# CH32X035 register map
Vendor: WCH Ltd.; File version: 1.3
Registers are 32-bit, read-write, reset 0x0 unless marked. A register's access mark holds for its fields unless they carry their own. Offsets are from the block's base; [hi:lo] are bit positions; {n}, {i} and the like mark numbered series.

## USART1 — Universal synchronous asynchronous receiver transmitter
Base 0x40013800
Same registers: USART2 0x40004400, USART3 0x40004800, UART4 0x40004C00
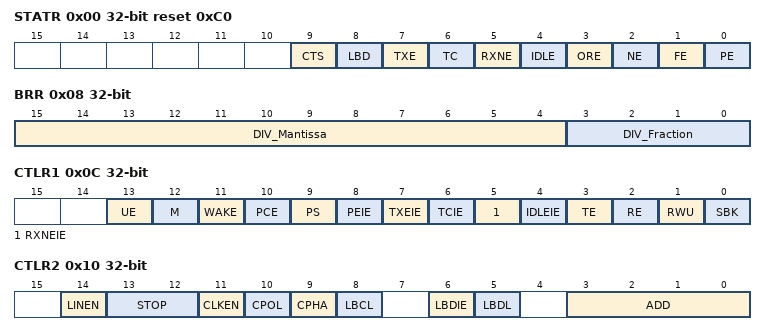
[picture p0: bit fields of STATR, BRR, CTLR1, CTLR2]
0x00 STATR access per field reset 0xC0 — Status register
  [9] CTS rw — CTS flag
  [8] LBD rw — LIN break detection flag
  [7] TXE ro — Transmit data register empty
  [6] TC rw — Transmission complete
  [5] RXNE rw — Read data register not empty
  [4] IDLE ro — IDLE line detected
  [3] ORE ro — Overrun error
  [2] NE ro — Noise error flag
  [1] FE ro — Framing error
  [0] PE ro — Parity error
0x04 DATAR — Data register
  [8:0] DR — Data value
0x08 BRR — Baud rate register
  [15:4] DIV_Mantissa — mantissa of USARTDIV
  [3:0] DIV_Fraction — fraction of USARTDIV
0x0C CTLR1 — Control register 1
  [13] UE — USART enable
  [12] M — Word length
  [11] WAKE — Wakeup method
  [10] PCE — Parity control enable
  [9] PS — Parity selection
  [8] PEIE — PE interrupt enable
  [7] TXEIE — TXE interrupt enable
  [6] TCIE — Transmission complete interrupt enable
  [5] RXNEIE — RXNE interrupt enable
  [4] IDLEIE — IDLE interrupt enable
  [3] TE — Transmitter enable
  [2] RE — Receiver enable
  [1] RWU — Receiver wakeup
  [0] SBK — Send break
0x10 CTLR2 — Control register 2
  [14] LINEN — LIN mode enable
  [13:12] STOP — STOP bits
  [11] CLKEN — Clock enable
  [10] CPOL — Clock polarity
  [9] CPHA — Clock phase
  [8] LBCL — Last bit clock pulse
  [6] LBDIE — LIN break detection interrupt enable
  [5] LBDL — lin break detection length
  [3:0] ADD — Address of the USART node
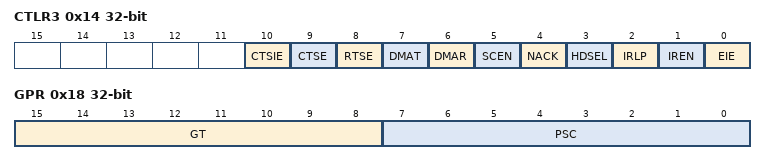
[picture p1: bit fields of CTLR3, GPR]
0x14 CTLR3 — Control register 3
  [10] CTSIE — CTS interrupt enable
  [9] CTSE — CTS enable
  [8] RTSE — RTS enable
  [7] DMAT — DMA enable transmitter
  [6] DMAR — DMA enable receiver
  [5] SCEN — Smartcard mode enable
  [4] NACK — Smartcard NACK enable
  [3] HDSEL — Half-duplex selection
  [2] IRLP — IrDA low-power
  [1] IREN — IrDA mode enable
  [0] EIE — Error interrupt enable
0x18 GPR — Guard time and prescaler register
  [15:8] GT — Guard time value
  [7:0] PSC — Prescaler value

## DBG — Debug support
Base 0xE000D000
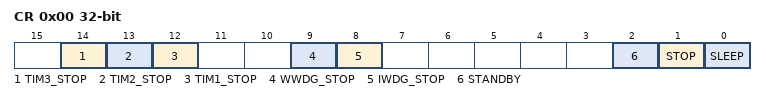
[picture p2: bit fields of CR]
0x00 CR — DBGMCU_CR
  [14] TIM3_STOP, [13] TIM2_STOP, [12] TIM1_STOP, [9] WWDG_STOP, [8] IWDG_STOP, [2] STANDBY, [1] STOP, [0] SLEEP

## USBFS — USB register
Base 0x40023400
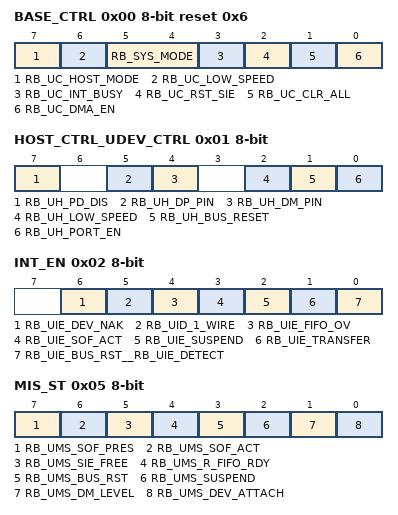
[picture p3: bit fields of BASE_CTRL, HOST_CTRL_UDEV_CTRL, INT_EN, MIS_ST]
0x00 BASE_CTRL 8-bit reset 0x6 — USB base control
  [7] RB_UC_HOST_MODE — enable USB host mode: 0=device mode, 1=host mode
  [6] RB_UC_LOW_SPEED
  [5:4] RB_SYS_MODE
  [3] RB_UC_INT_BUSY — enable automatic responding busy for device mode or automatic pause for host mode during interrupt flag UIF_TRANSFER valid
  [2] RB_UC_RST_SIE — force reset USB SIE, need software clear
  [1] RB_UC_CLR_ALL — force clear FIFO and count of USB
  [0] RB_UC_DMA_EN — DMA enable and DMA interrupt enable for USB
0x01 HOST_CTRL_UDEV_CTRL 8-bit access per field — USB HOST control_UDEV_CTRL
  [7] RB_UH_PD_DIS rw, [5] RB_UH_DP_PIN ro, [4] RB_UH_DM_PIN ro, [2] RB_UH_LOW_SPEED rw, [1] RB_UH_BUS_RESET rw, [0] RB_UH_PORT_EN rw
0x02 INT_EN 8-bit — USB interrupt enable
  [6] RB_UIE_DEV_NAK
  [5] RB_UID_1_WIRE — USB single-line mode enable
  [4] RB_UIE_FIFO_OV — enable interrupt for FIFO overflow
  [3] RB_UIE_SOF_ACT — indicate host SOF timer action status for USB host
  [2] RB_UIE_SUSPEND — enable interrupt for USB suspend or resume event
  [1] RB_UIE_TRANSFER — enable interrupt for USB transfer completion
  [0] RB_UIE_BUS_RST__RB_UIE_DETECT — enable interrupt for USB bus reset event for USB device mode;enable interrupt for USB device detected event for USB host mode
0x03 DEV_ADDR 8-bit — USB device address
  [6:0] MASK_USB_ADDR — bit mask for USB device address
0x05 MIS_ST 8-bit ro — USB_MIS_ST
  [7] RB_UMS_SOF_PRES, [6] RB_UMS_SOF_ACT, [5] RB_UMS_SIE_FREE, [4] RB_UMS_R_FIFO_RDY, [3] RB_UMS_BUS_RST, [2] RB_UMS_SUSPEND, [1] RB_UMS_DM_LEVEL, [0] RB_UMS_DEV_ATTACH
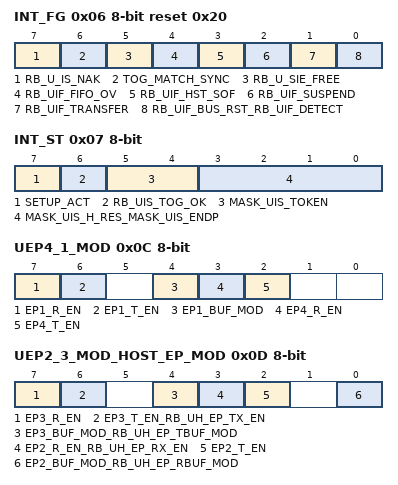
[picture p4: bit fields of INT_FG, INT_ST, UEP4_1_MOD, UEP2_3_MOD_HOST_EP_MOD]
0x06 INT_FG 8-bit access per field reset 0x20 — USB_INT_FG
  [7] RB_U_IS_NAK ro, [6] TOG_MATCH_SYNC ro, [5] RB_U_SIE_FREE ro, [4] RB_UIF_FIFO_OV rw, [3] RB_UIF_HST_SOF rw, [2] RB_UIF_SUSPEND rw, [1] RB_UIF_TRANSFER rw, [0] RB_UIF_BUS_RST_RB_UIF_DETECT rw
0x07 INT_ST 8-bit ro — USB_INT_ST
  [7] SETUP_ACT, [6] RB_UIS_TOG_OK, [5:4] MASK_UIS_TOKEN, [3:0] MASK_UIS_H_RES_MASK_UIS_ENDP
0x08 RX_LEN 16-bit ro — USB_RX_LEN
  [6:0] USB_RX_LEN
0x0C UEP4_1_MOD 8-bit
  [7] EP1_R_EN, [6] EP1_T_EN, [4] EP1_BUF_MOD, [3] EP4_R_EN, [2] EP4_T_EN
0x0D UEP2_3_MOD_HOST_EP_MOD 8-bit
  [7] EP3_R_EN — EP1_R_EN
  [6] EP3_T_EN_RB_UH_EP_TX_EN — EP1_T_EN_RB_UH_EP_TX_EN
  [4] EP3_BUF_MOD_RB_UH_EP_TBUF_MOD — EP1_BUF_MOD_RB_UH_EP_TBUF_MOD
  [3] EP2_R_EN_RB_UH_EP_RX_EN
  [2] EP2_T_EN
  [0] EP2_BUF_MOD_RB_UH_EP_RBUF_MOD
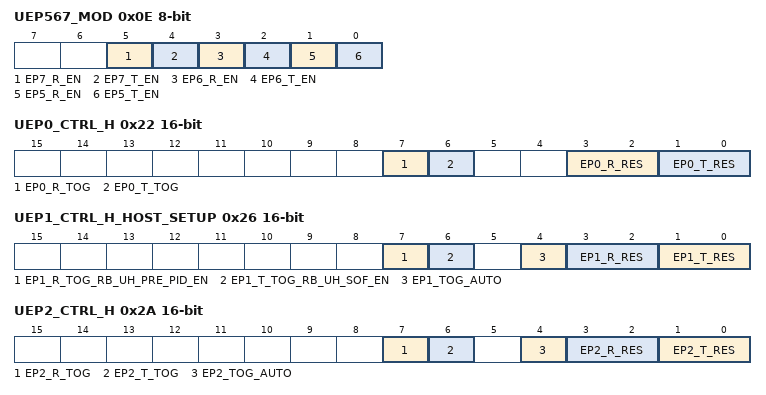
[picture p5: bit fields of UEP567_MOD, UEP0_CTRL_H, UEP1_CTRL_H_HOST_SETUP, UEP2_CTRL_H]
0x0E UEP567_MOD 8-bit
  [5] EP7_R_EN, [4] EP7_T_EN, [3] EP6_R_EN, [2] EP6_T_EN, [1] EP5_R_EN, [0] EP5_T_EN
0x10 UEP0_DMA
  [14:0] EP0_BUF_ADDR
0x14 UEP1_DMA
  [14:0] EP1_BUF_ADDR
0x18 UEP2_DMA_HOST_RX_DMA
  [14:0] EP2_BUF_ADDR_UH_RX_DMA
0x1C UEP3_DMA_HOST_TX_DMA
  [14:0] EP3_BUF_ADDR_UH_TX_DMA
{0x20+4i} UEP{i}_TX_LEN 16-bit (i=0..4)
  [6:0] EP{i}_T_LEN
0x22 UEP0_CTRL_H 16-bit
  [7] EP0_R_TOG, [6] EP0_T_TOG, [3:2] EP0_R_RES, [1:0] EP0_T_RES
0x26 UEP1_CTRL_H_HOST_SETUP 16-bit
  [7] EP1_R_TOG_RB_UH_PRE_PID_EN, [6] EP1_T_TOG_RB_UH_SOF_EN, [4] EP1_TOG_AUTO, [3:2] EP1_R_RES, [1:0] EP1_T_RES
0x2A UEP2_CTRL_H 16-bit
  [7] EP2_R_TOG, [6] EP2_T_TOG, [4] EP2_TOG_AUTO, [3:2] EP2_R_RES, [1:0] EP2_T_RES
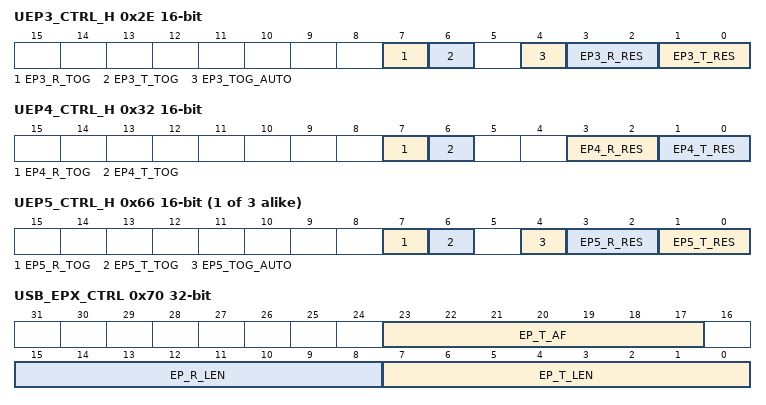
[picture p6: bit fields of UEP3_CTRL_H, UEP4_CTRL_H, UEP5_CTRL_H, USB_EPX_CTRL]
0x2E UEP3_CTRL_H 16-bit
  [7] EP3_R_TOG, [6] EP3_T_TOG, [4] EP3_TOG_AUTO, [3:2] EP3_R_RES, [1:0] EP3_T_RES
0x32 UEP4_CTRL_H 16-bit
  [7] EP4_R_TOG, [6] EP4_T_TOG, [3:2] EP4_R_RES, [1:0] EP4_T_RES
{0x40+4i} UEP{i}_DMA (i=5..7)
  [14:0] EP{i}_BUF_ADDR
{0x50+4i} UEP{i}_TX_LEN 16-bit (i=5..7)
  [6:0] EP{i}_T_LEN
{0x52+4i} UEP{i}_CTRL_H 16-bit (i=5..7)
  [7] EP{i}_R_TOG, [6] EP{i}_T_TOG, [4] EP{i}_TOG_AUTO, [3:2] EP{i}_R_RES, [1:0] EP{i}_T_RES
0x70 USB_EPX_CTRL
  [23:17] EP_T_AF
  [15:8] EP_R_LEN — EP5_R_LEN
  [7:0] EP_T_LEN — EP5_T_LEN
